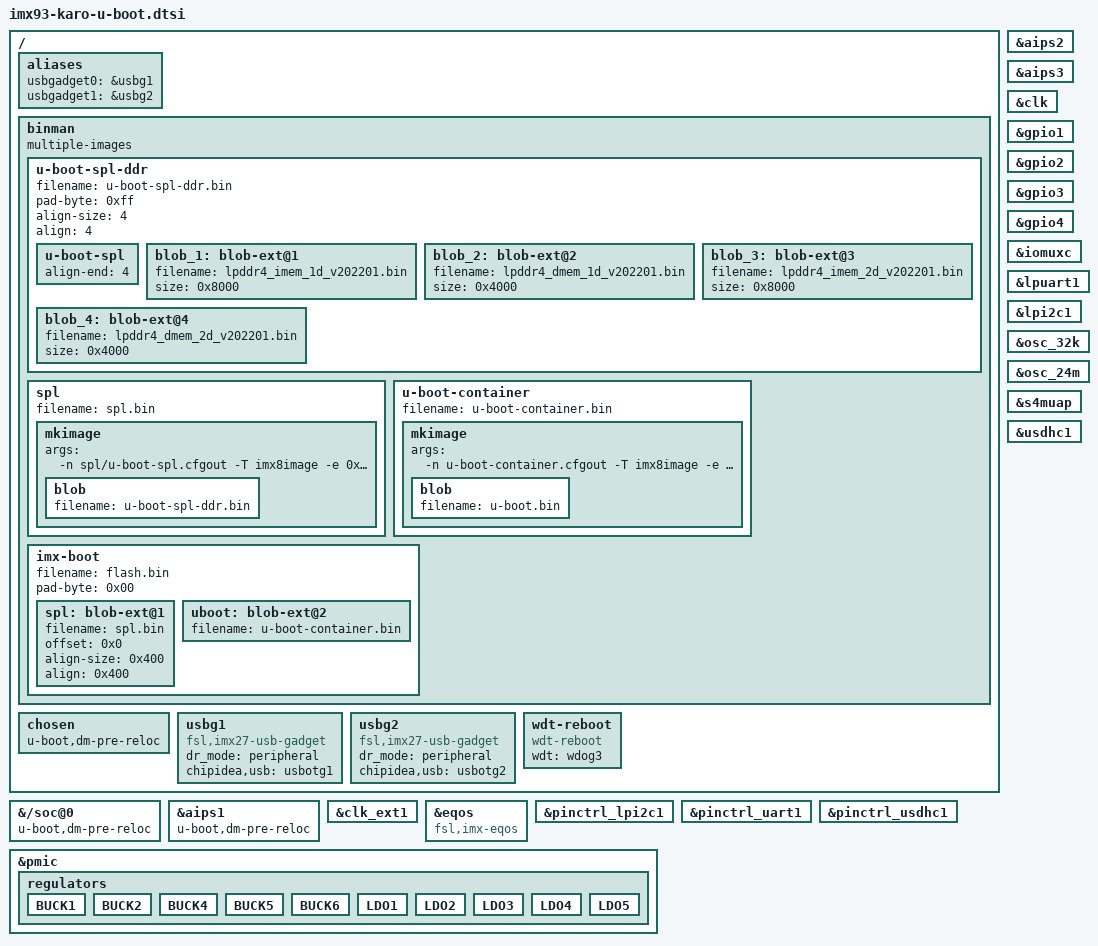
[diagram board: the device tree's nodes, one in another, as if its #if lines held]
// SPDX-License-Identifier: (GPL-2.0 or MIT)
/*
 * Copyright 2023 Lothar Waßmann <LW@KARO-electronics.de>
 */

/ {
	aliases {
		usbgadget0 = &usbg1;
		usbgadget1 = &usbg2;
	};

#ifdef CONFIG_BINMAN
	binman: binman {
		multiple-images;
	};
#endif
	chosen {
		u-boot,dm-spl;
		u-boot,dm-pre-reloc;
	};

	usbg1: usbg1 {
		compatible = "fsl,imx27-usb-gadget";
		dr_mode = "peripheral";
		chipidea,usb = <&usbotg1>;
		status = "okay";
	};

	usbg2: usbg2 {
		compatible = "fsl,imx27-usb-gadget";
		dr_mode = "peripheral";
		chipidea,usb = <&usbotg2>;
		status = "okay";
	};

	wdt-reboot {
		compatible = "wdt-reboot";
		wdt = <&wdog3>;
		u-boot,dm-spl;
	};
};

&{/soc@0} {
	u-boot,dm-spl;
	u-boot,dm-pre-reloc;
};

&aips1 {
	u-boot,dm-spl;
	u-boot,dm-pre-reloc;
};

&aips2 {
	u-boot,dm-spl;
};

&aips3 {
	u-boot,dm-spl;
};

#ifdef CONFIG_BINMAN
&binman {
	 u-boot-spl-ddr {
		filename = "u-boot-spl-ddr.bin";
		pad-byte = <0xff>;
		align-size = <4>;
		align = <4>;

		u-boot-spl {
			align-end = <4>;
		};

		blob_1: blob-ext@1 {
			filename = "lpddr4_imem_1d_v202201.bin";
			size = <0x8000>;
		};

		blob_2: blob-ext@2 {
			filename = "lpddr4_dmem_1d_v202201.bin";
			size = <0x4000>;
		};

		blob_3: blob-ext@3 {
			filename = "lpddr4_imem_2d_v202201.bin";
			size = <0x8000>;
		};

		blob_4: blob-ext@4 {
			filename = "lpddr4_dmem_2d_v202201.bin";
			size = <0x4000>;
		};
	};

	spl {
		filename = "spl.bin";

		mkimage {
			args = "-n spl/u-boot-spl.cfgout -T imx8image -e 0x2049a000";

			blob {
				filename = "u-boot-spl-ddr.bin";
			};
		};
	};

	u-boot-container {
		filename = "u-boot-container.bin";

		mkimage {
			args = "-n u-boot-container.cfgout -T imx8image -e 0x0";

			blob {
				filename = "u-boot.bin";
			};
		};
	};

	imx-boot {
		filename = "flash.bin";
		pad-byte = <0x00>;

		spl: blob-ext@1 {
			filename = "spl.bin";
			offset = <0x0>;
			align-size = <0x400>;
			align = <0x400>;
		};

		uboot: blob-ext@2 {
			filename = "u-boot-container.bin";
		};
	};
};
#endif

&clk {
	u-boot,dm-spl;
};

&clk_ext1 {
	u-boot,dm-spl;
};

&eqos {
	compatible = "fsl,imx-eqos";
};

&gpio1 {
	u-boot,dm-spl;
};

&gpio2 {
	u-boot,dm-spl;
};

&gpio3 {
	u-boot,dm-spl;
};

&gpio4 {
	u-boot,dm-spl;
};

&iomuxc {
	u-boot,dm-spl;
};

&lpuart1 {
	u-boot,dm-spl;
};

&lpi2c1 {
	u-boot,dm-spl;
};

&osc_32k {
	u-boot,dm-spl;
};

&osc_24m {
	u-boot,dm-spl;
};

&pinctrl_lpi2c1 {
	u-boot,dm-spl;
};

&pinctrl_uart1 {
	u-boot,dm-spl;
};

&pinctrl_usdhc1 {
	u-boot,dm-spl;
};

&pmic {
	u-boot,dm-spl;

	regulators {
		u-boot,dm-spl;

		BUCK1 {
			u-boot,dm-spl;
		};

		BUCK2 {
			u-boot,dm-spl;
		};

		BUCK4 {
			u-boot,dm-spl;
		};

		BUCK5 {
			u-boot,dm-spl;
		};

		BUCK6 {
			u-boot,dm-spl;
		};

		LDO1 {
			u-boot,dm-spl;
		};

		LDO2 {
			u-boot,dm-spl;
		};

		LDO3 {
			u-boot,dm-spl;
		};

		LDO4 {
			u-boot,dm-spl;
		};

		LDO5 {
			u-boot,dm-spl;
		};
	};
};

&s4muap {
	u-boot,dm-spl;
	status = "okay";
};

&usdhc1 {
	u-boot,dm-spl;
};
